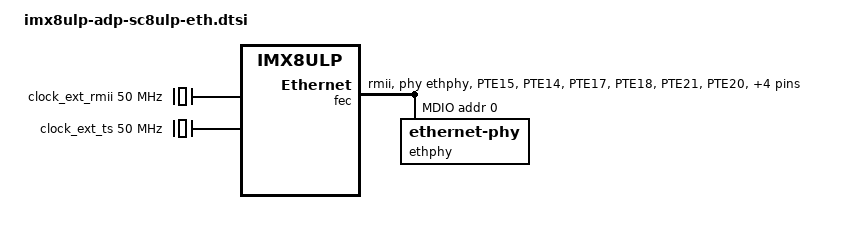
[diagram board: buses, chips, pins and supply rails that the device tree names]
// SPDX-License-Identifier: GPL-2.0+
/*
 * Copyright 2022 NXP
 */

/ {

	clock_ext_rmii: clock-ext-rmii {
		compatible = "fixed-clock";
		clock-frequency = <50000000>;
		clock-output-names = "ext_rmii_clk";
		#clock-cells = <0>;
	};

	clock_ext_ts: clock-ext-ts {
		compatible = "fixed-clock";
		/* External ts clock is 50MHZ from PHY on EVK board. */
		clock-frequency = <50000000>;
		clock-output-names = "ext_ts_clk";
		#clock-cells = <0>;
	};

};

&fec {
	pinctrl-names = "default", "sleep";
	pinctrl-0 = <&pinctrl_enet>;
	pinctrl-1 = <&pinctrl_enet>;
	clocks = <&cgc1 IMX8ULP_CLK_XBAR_DIVBUS>,
		 <&pcc4 IMX8ULP_CLK_ENET>,
		 <&cgc1 IMX8ULP_CLK_ENET_TS_SEL>,
		 <&clock_ext_rmii>;
	clock-names = "ipg", "ahb", "ptp", "enet_clk_ref";
	assigned-clocks = <&cgc1 IMX8ULP_CLK_ENET_TS_SEL>;
	assigned-clock-parents = <&clock_ext_ts>;
	phy-mode = "rmii";
	phy-handle = <&ethphy>;
	status = "okay";

	mdio {
		#address-cells = <1>;
		#size-cells = <0>;

		ethphy: ethernet-phy@0 {
			reg = <0>;
			micrel,led-mode = <1>;
		};
	};
};


&iomuxc1 {
	pinctrl_enet: enetgrp {
		fsl,pins = <
			MX8ULP_PAD_PTE15__ENET0_MDC     0x43
			MX8ULP_PAD_PTE14__ENET0_MDIO    0x43
			MX8ULP_PAD_PTE17__ENET0_RXER    0x43
			MX8ULP_PAD_PTE18__ENET0_CRS_DV  0x43
			MX8ULP_PAD_PTE21__ENET0_RXD0	0x43
			MX8ULP_PAD_PTE20__ENET0_RXD1    0x43
			MX8ULP_PAD_PTE16__ENET0_TXEN    0x43
			MX8ULP_PAD_PTE23__ENET0_TXD0    0x43
			MX8ULP_PAD_PTE22__ENET0_TXD1    0x43
			MX8ULP_PAD_PTE19__ENET0_REFCLK  0x43
		>;
	};
};
